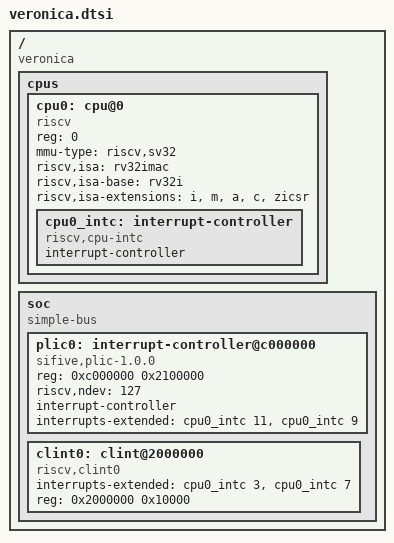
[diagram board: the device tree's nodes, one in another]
// SPDX-License-Identifier: (GPL-2.0 OR MIT)

/dts-v1/;

#include <dt-bindings/clock/sifive-fu540-prci.h>
#include <dt-bindings/interrupt-controller/irq.h>

/ {
	#address-cells = <1>;
	#size-cells = <1>;
	compatible = "veronica";

	cpus: cpus {
		#address-cells = <1>;
		#size-cells = <0>;
		
		cpu0: cpu@0 {
			compatible = "riscv";
			device_type = "cpu";
			status = "okay";
			reg = <0>;
			mmu-type = "riscv,sv32";
			riscv,isa = "rv32imac";
			riscv,isa-base = "rv32i";
			riscv,isa-extensions = "i", "m", "a", "c", "zicsr";
			cpu0_intc: interrupt-controller {
				#interrupt-cells = <1>;
				#address-cells = <1>;
				compatible = "riscv,cpu-intc";
				interrupt-controller;
			};
		};
	};
	
	soc: soc {
		#address-cells = <1>;
		#size-cells = <1>;
		compatible = "simple-bus";
		ranges;
		
		plic0: interrupt-controller@c000000 {
      #address-cells = <1>;
      status="okay";
			compatible = "sifive,plic-1.0.0", "sifive,fu540-c000-plic";
			reg = <0xc000000 0x2100000>;
      #interrupt-cells = <1>;
			riscv,ndev = <127>;
			interrupt-controller;
			interrupts-extended = <&cpu0_intc 11>, <&cpu0_intc 9>;
		};
		
		clint0: clint@2000000 {
      status="okay";
			compatible = "riscv,clint0";
			interrupts-extended = <&cpu0_intc 3>, <&cpu0_intc 7>;
			reg = <0x2000000 0x10000>;
		};
	};
};
